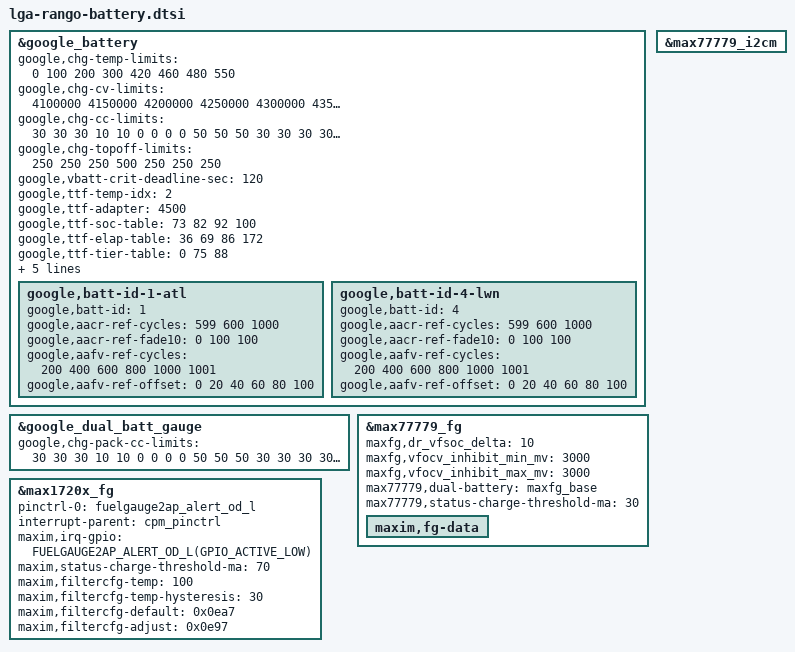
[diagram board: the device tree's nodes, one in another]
// SPDX-License-Identifier: GPL-2.0-only
/*
 * Battery device tree entries specific to Rango
 *
 * Copyright 2024 Google LLC
 *
 */

#include "google-base/platform/lga-platform-battery.dtsi"
#include "google-base/platform/lga-dual-battery-common.dtsi"

&google_battery {
	google,chg-temp-limits = <0 100 200 300 420 460 480 550>;
	google,chg-cv-limits = <
		4100000 4150000 4200000 4250000 4300000 4350000 4370000 4480000 4500000>;
	google,chg-cc-limits = <
		 30  30  30  10  10   0   0   0   0
		 50  50  50  30  30  30  30  30  30
		110 110 105 105 105 105 105  50  50
		110 110 105 105 105 105 105  50  50
		 90  90  90  90  90  90  50  50   0
		 50  50  50  50   0   0   0   0   0
		 30   0   0   0   0   0   0   0   0
	>;

	google,chg-topoff-limits = <250 250 250 500 250 250 250>;

	google,vbatt-crit-deadline-sec = <120>;

	google,ttf-temp-idx= <2>;
	google,ttf-adapter = <4500>;
	google,ttf-soc-table =  <73 82 92 100>;
	google,ttf-elap-table = <36 69 86 172>;
	google,ttf-tier-table = <0 75 88>;

	google,aacr-config = <1>; /* enabled, no opt out */
	google,aafv-config = <1>; /* enabled, no opt out */

	/* 90% after 600 cycles, 80% after 1000 cycles */
	google,aacr-algo = <3>;
	google,aacr-cliff-capacity-rate = <80>;
	google,aacr-cycle-max = <1000>;

	google,batt-id-1-atl {
		google,batt-id = <1>;
		google,aacr-ref-cycles = <599 600 1000>;
		google,aacr-ref-fade10 = <  0 100  100>;
		google,aafv-ref-cycles = <200 400 600 800 1000 1001>;
		google,aafv-ref-offset = <  0  20  40  60   80  100>;
	};
	google,batt-id-4-lwn {
		google,batt-id = <4>;
		google,aacr-ref-cycles = <599 600 1000>;
		google,aacr-ref-fade10 = <  0 100  100>;
		google,aafv-ref-cycles = <200 400 600 800 1000 1001>;
		google,aafv-ref-offset = <  0  20  40  60   80  100>;
	};
};

&google_dual_batt_gauge {
	google,chg-pack-cc-limits = <
		 30  30  30  10  10   0   0   0   0
		 50  50  50  30  30  30  30  30  30
		115 115 110 110 110 110 110  50  50
		115 115 110 110 110 110 110  50  50
		 90  90  90  90  90  90  50  50   0
		 50  50  50  50   0   0   0   0   0
		 30   0   0   0   0   0   0   0   0
	>;
};

&max77779_fg {
	maxfg,dr_vfsoc_delta = <10>;
	maxfg,vfocv_inhibit_min_mv = <3000>;
	maxfg,vfocv_inhibit_max_mv = <3000>;
	max77779,dual-battery = "maxfg_base";
	max77779,status-charge-threshold-ma = <30>;
	maxim,fg-data {
		#include "lga-rango-battery-data.dtsi"
	};
};

&max77779_i2cm {
	#include "google-base/platform/lga-max1720x-fg.dtsi"
};


&max1720x_fg {
	pinctrl-0 = <&fuelgauge2ap_alert_od_l>;

	interrupt-parent = <&cpm_pinctrl>;
	maxim,irq-gpio = <FUELGAUGE2AP_ALERT_OD_L(GPIO_ACTIVE_LOW)>;

	maxim,status-charge-threshold-ma = <70>;

	maxim,filtercfg-temp = <100>;
	maxim,filtercfg-temp-hysteresis = <30>;
	maxim,filtercfg-default = /bits/ 16 <0x0ea7>;
	maxim,filtercfg-adjust = /bits/ 16 <0x0e97>;
};
